VERSION ""

NS_ :

BS_:

BU_:

BO_ 1224 LF_IRTS_Brake_5: 2 Vector__XXX
 SG_ LF_Sensor_Temp : 7|16@0+ (0.1,-100) [-100|6453.5] "°C" Vector__XXX

BO_ 1229 RF_IRTS_Brake_5: 2 Vector__XXX
 SG_ RF_Sensor_Temp : 7|16@0+ (0.1,-100) [-100|6453.5] "°C" Vector__XXX

BO_ 1239 RR_IRTS_Brake_5: 2 Vector__XXX
 SG_ RR_Sensor_Temp : 7|16@0+ (0.1,-100) [-100|6453.5] "°C" Vector__XXX

BO_ 1234 LR_IRTS_Brake_5: 2 Vector__XXX
 SG_ LR_Sensor_Temp : 7|16@0+ (0.1,-100) [-100|6453.5] "°C" Vector__XXX

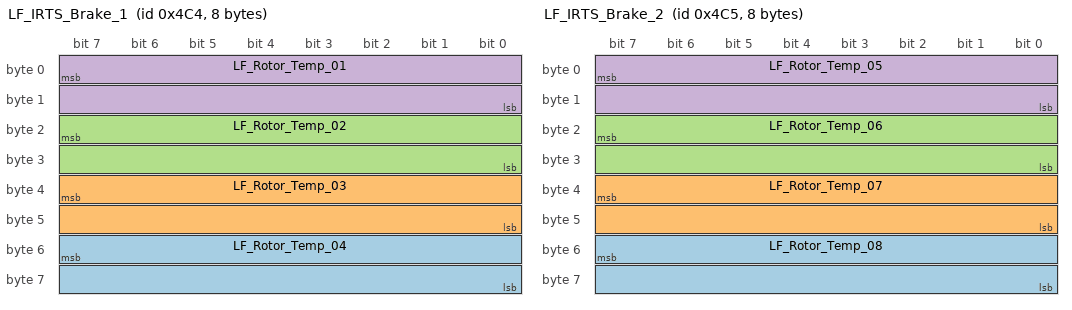
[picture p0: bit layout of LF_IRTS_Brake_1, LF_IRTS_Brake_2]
BO_ 1220 LF_IRTS_Brake_1: 8 Vector__XXX
 SG_ LF_Rotor_Temp_04 : 55|16@0+ (0.1,-100) [-100|6453.5] "°C" Vector__XXX
 SG_ LF_Rotor_Temp_03 : 39|16@0+ (0.1,-100) [-100|6453.5] "°C" Vector__XXX
 SG_ LF_Rotor_Temp_02 : 23|16@0+ (0.1,-100) [-100|6453.5] "°C" Vector__XXX
 SG_ LF_Rotor_Temp_01 : 7|16@0+ (0.1,-100) [-100|6453.5] "°C" Vector__XXX

BO_ 1221 LF_IRTS_Brake_2: 8 Vector__XXX
 SG_ LF_Rotor_Temp_08 : 55|16@0+ (0.1,-100) [-100|6453.5] "°C" Vector__XXX
 SG_ LF_Rotor_Temp_07 : 39|16@0+ (0.1,-100) [-100|6453.5] "°C" Vector__XXX
 SG_ LF_Rotor_Temp_06 : 23|16@0+ (0.1,-100) [-100|6453.5] "°C" Vector__XXX
 SG_ LF_Rotor_Temp_05 : 7|16@0+ (0.1,-100) [-100|6453.5] "°C" Vector__XXX

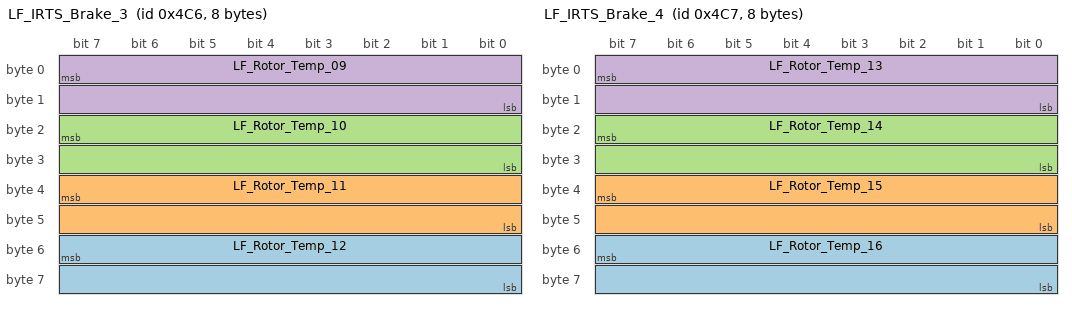
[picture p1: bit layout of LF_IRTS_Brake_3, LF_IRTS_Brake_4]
BO_ 1222 LF_IRTS_Brake_3: 8 Vector__XXX
 SG_ LF_Rotor_Temp_12 : 55|16@0+ (0.1,-100) [-100|6453.5] "°C" Vector__XXX
 SG_ LF_Rotor_Temp_11 : 39|16@0+ (0.1,-100) [-100|6453.5] "°C" Vector__XXX
 SG_ LF_Rotor_Temp_10 : 23|16@0+ (0.1,-100) [-100|6453.5] "°C" Vector__XXX
 SG_ LF_Rotor_Temp_09 : 7|16@0+ (0.1,-100) [-100|6453.5] "°C" Vector__XXX

BO_ 1223 LF_IRTS_Brake_4: 8 Vector__XXX
 SG_ LF_Rotor_Temp_16 : 55|16@0+ (0.1,-100) [-100|6453.5] "°C" Vector__XXX
 SG_ LF_Rotor_Temp_15 : 39|16@0+ (0.1,-100) [-100|6453.5] "°C" Vector__XXX
 SG_ LF_Rotor_Temp_14 : 23|16@0+ (0.1,-100) [-100|6453.5] "°C" Vector__XXX
 SG_ LF_Rotor_Temp_13 : 7|16@0+ (0.1,-100) [-100|6453.5] "°C" Vector__XXX

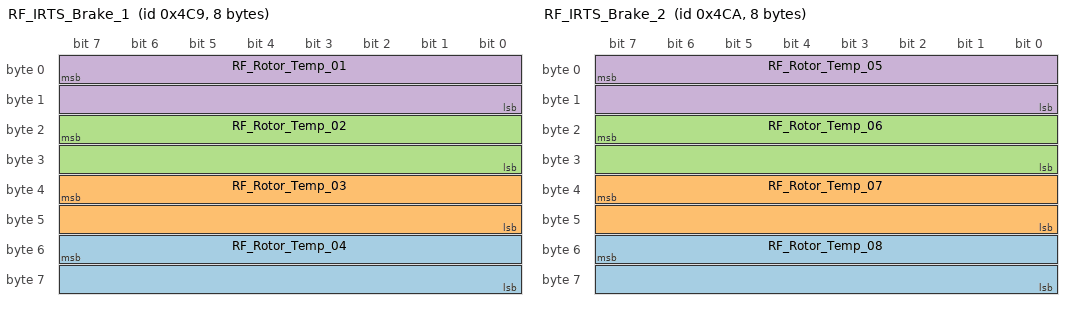
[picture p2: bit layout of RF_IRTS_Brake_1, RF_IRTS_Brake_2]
BO_ 1225 RF_IRTS_Brake_1: 8 Vector__XXX
 SG_ RF_Rotor_Temp_04 : 55|16@0+ (0.1,-100) [-100|6453.5] "°C" Vector__XXX
 SG_ RF_Rotor_Temp_03 : 39|16@0+ (0.1,-100) [-100|6453.5] "°C" Vector__XXX
 SG_ RF_Rotor_Temp_02 : 23|16@0+ (0.1,-100) [-100|6453.5] "°C" Vector__XXX
 SG_ RF_Rotor_Temp_01 : 7|16@0+ (0.1,-100) [-100|6453.5] "°C" Vector__XXX

BO_ 1226 RF_IRTS_Brake_2: 8 Vector__XXX
 SG_ RF_Rotor_Temp_08 : 55|16@0+ (0.1,-100) [-100|6453.5] "°C" Vector__XXX
 SG_ RF_Rotor_Temp_07 : 39|16@0+ (0.1,-100) [-100|6453.5] "°C" Vector__XXX
 SG_ RF_Rotor_Temp_06 : 23|16@0+ (0.1,-100) [-100|6453.5] "°C" Vector__XXX
 SG_ RF_Rotor_Temp_05 : 7|16@0+ (0.1,-100) [-100|6453.5] "°C" Vector__XXX

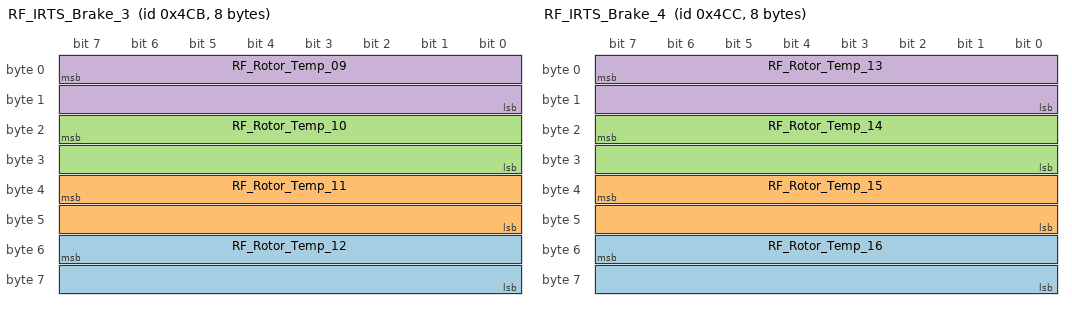
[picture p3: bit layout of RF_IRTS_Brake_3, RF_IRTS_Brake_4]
BO_ 1227 RF_IRTS_Brake_3: 8 Vector__XXX
 SG_ RF_Rotor_Temp_12 : 55|16@0+ (0.1,-100) [-100|6453.5] "°C" Vector__XXX
 SG_ RF_Rotor_Temp_11 : 39|16@0+ (0.1,-100) [-100|6453.5] "°C" Vector__XXX
 SG_ RF_Rotor_Temp_10 : 23|16@0+ (0.1,-100) [-100|6453.5] "°C" Vector__XXX
 SG_ RF_Rotor_Temp_09 : 7|16@0+ (0.1,-100) [-100|6453.5] "°C" Vector__XXX

BO_ 1228 RF_IRTS_Brake_4: 8 Vector__XXX
 SG_ RF_Rotor_Temp_16 : 55|16@0+ (0.1,-100) [-100|6453.5] "°C" Vector__XXX
 SG_ RF_Rotor_Temp_15 : 39|16@0+ (0.1,-100) [-100|6453.5] "°C" Vector__XXX
 SG_ RF_Rotor_Temp_14 : 23|16@0+ (0.1,-100) [-100|6453.5] "°C" Vector__XXX
 SG_ RF_Rotor_Temp_13 : 7|16@0+ (0.1,-100) [-100|6453.5] "°C" Vector__XXX

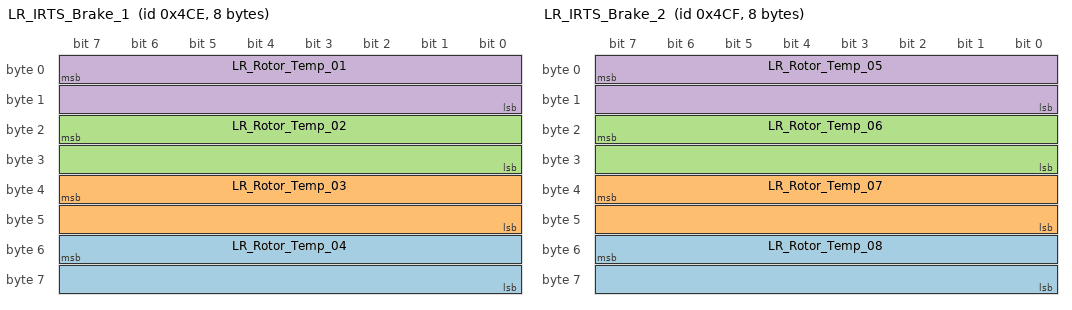
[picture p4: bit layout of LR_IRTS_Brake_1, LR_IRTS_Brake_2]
BO_ 1230 LR_IRTS_Brake_1: 8 Vector__XXX
 SG_ LR_Rotor_Temp_04 : 55|16@0+ (0.1,-100) [-100|6453.5] "°C" Vector__XXX
 SG_ LR_Rotor_Temp_03 : 39|16@0+ (0.1,-100) [-100|6453.5] "°C" Vector__XXX
 SG_ LR_Rotor_Temp_02 : 23|16@0+ (0.1,-100) [-100|6453.5] "°C" Vector__XXX
 SG_ LR_Rotor_Temp_01 : 7|16@0+ (0.1,-100) [-100|6453.5] "°C" Vector__XXX

BO_ 1231 LR_IRTS_Brake_2: 8 Vector__XXX
 SG_ LR_Rotor_Temp_08 : 55|16@0+ (0.1,-100) [-100|6453.5] "°C" Vector__XXX
 SG_ LR_Rotor_Temp_07 : 39|16@0+ (0.1,-100) [-100|6453.5] "°C" Vector__XXX
 SG_ LR_Rotor_Temp_06 : 23|16@0+ (0.1,-100) [-100|6453.5] "°C" Vector__XXX
 SG_ LR_Rotor_Temp_05 : 7|16@0+ (0.1,-100) [-100|6453.5] "°C" Vector__XXX

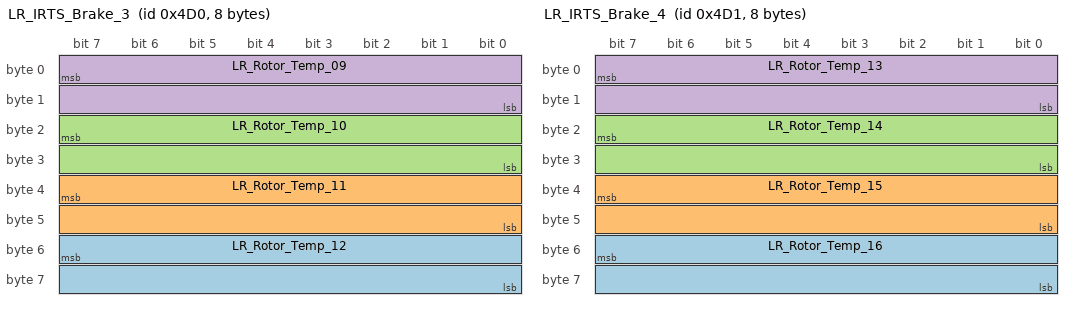
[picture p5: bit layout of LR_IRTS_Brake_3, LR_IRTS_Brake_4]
BO_ 1232 LR_IRTS_Brake_3: 8 Vector__XXX
 SG_ LR_Rotor_Temp_12 : 55|16@0+ (0.1,-100) [-100|6453.5] "°C" Vector__XXX
 SG_ LR_Rotor_Temp_11 : 39|16@0+ (0.1,-100) [-100|6453.5] "°C" Vector__XXX
 SG_ LR_Rotor_Temp_10 : 23|16@0+ (0.1,-100) [-100|6453.5] "°C" Vector__XXX
 SG_ LR_Rotor_Temp_09 : 7|16@0+ (0.1,-100) [-100|6453.5] "°C" Vector__XXX

BO_ 1233 LR_IRTS_Brake_4: 8 Vector__XXX
 SG_ LR_Rotor_Temp_16 : 55|16@0+ (0.1,-100) [-100|6453.5] "°C" Vector__XXX
 SG_ LR_Rotor_Temp_15 : 39|16@0+ (0.1,-100) [-100|6453.5] "°C" Vector__XXX
 SG_ LR_Rotor_Temp_14 : 23|16@0+ (0.1,-100) [-100|6453.5] "°C" Vector__XXX
 SG_ LR_Rotor_Temp_13 : 7|16@0+ (0.1,-100) [-100|6453.5] "°C" Vector__XXX

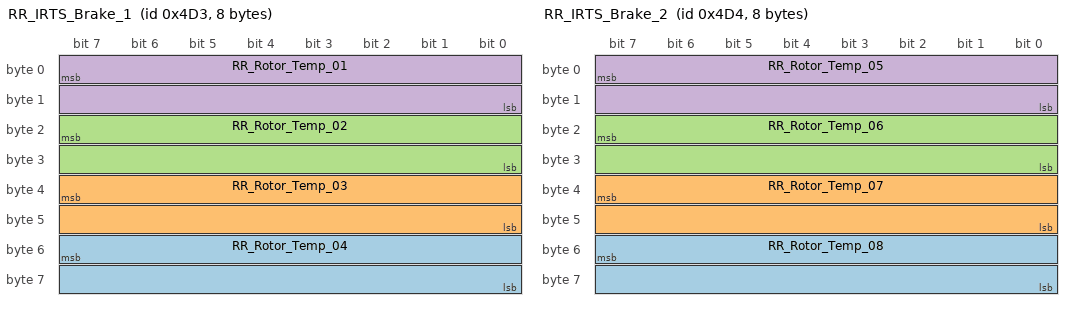
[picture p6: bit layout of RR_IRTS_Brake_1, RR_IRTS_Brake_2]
BO_ 1235 RR_IRTS_Brake_1: 8 Vector__XXX
 SG_ RR_Rotor_Temp_04 : 55|16@0+ (0.1,-100) [-100|6453.5] "°C" Vector__XXX
 SG_ RR_Rotor_Temp_03 : 39|16@0+ (0.1,-100) [-100|6453.5] "°C" Vector__XXX
 SG_ RR_Rotor_Temp_02 : 23|16@0+ (0.1,-100) [-100|6453.5] "°C" Vector__XXX
 SG_ RR_Rotor_Temp_01 : 7|16@0+ (0.1,-100) [-100|6453.5] "°C" Vector__XXX

BO_ 1236 RR_IRTS_Brake_2: 8 Vector__XXX
 SG_ RR_Rotor_Temp_08 : 55|16@0+ (0.1,-100) [-100|6453.5] "°C" Vector__XXX
 SG_ RR_Rotor_Temp_07 : 39|16@0+ (0.1,-100) [-100|6453.5] "°C" Vector__XXX
 SG_ RR_Rotor_Temp_06 : 23|16@0+ (0.1,-100) [-100|6453.5] "°C" Vector__XXX
 SG_ RR_Rotor_Temp_05 : 7|16@0+ (0.1,-100) [-100|6453.5] "°C" Vector__XXX

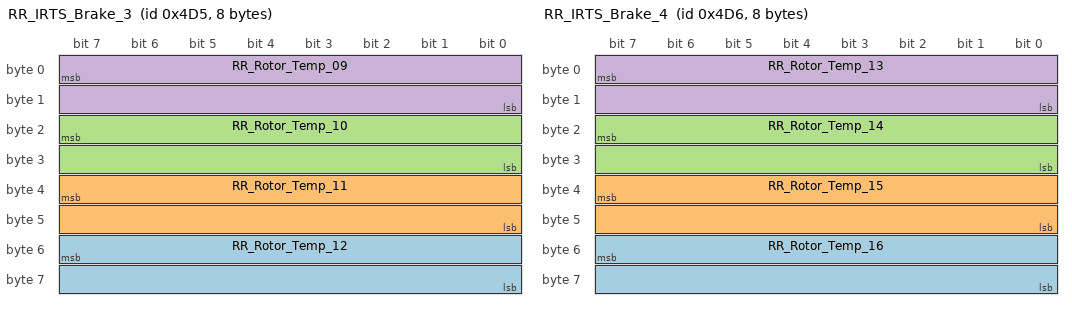
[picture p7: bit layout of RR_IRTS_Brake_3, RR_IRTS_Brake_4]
BO_ 1237 RR_IRTS_Brake_3: 8 Vector__XXX
 SG_ RR_Rotor_Temp_12 : 55|16@0+ (0.1,-100) [-100|6453.5] "°C" Vector__XXX
 SG_ RR_Rotor_Temp_11 : 39|16@0+ (0.1,-100) [-100|6453.5] "°C" Vector__XXX
 SG_ RR_Rotor_Temp_10 : 23|16@0+ (0.1,-100) [-100|6453.5] "°C" Vector__XXX
 SG_ RR_Rotor_Temp_09 : 7|16@0+ (0.1,-100) [-100|6453.5] "°C" Vector__XXX

BO_ 1238 RR_IRTS_Brake_4: 8 Vector__XXX
 SG_ RR_Rotor_Temp_16 : 55|16@0+ (0.1,-100) [-100|6453.5] "°C" Vector__XXX
 SG_ RR_Rotor_Temp_15 : 39|16@0+ (0.1,-100) [-100|6453.5] "°C" Vector__XXX
 SG_ RR_Rotor_Temp_14 : 23|16@0+ (0.1,-100) [-100|6453.5] "°C" Vector__XXX
 SG_ RR_Rotor_Temp_13 : 7|16@0+ (0.1,-100) [-100|6453.5] "°C" Vector__XXX
